VERSION ""

NS_ :

BS_:

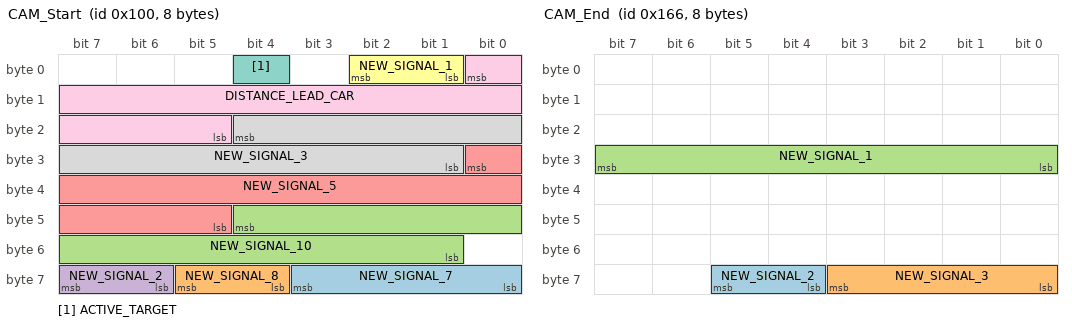
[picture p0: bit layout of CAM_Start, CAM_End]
BO_ 256 CAM_Start: 8 XXX
 SG_ NEW_SIGNAL_7 : 56|4@1+ (1,0) [0|15] "" XXX
 SG_ NEW_SIGNAL_8 : 61|2@0+ (1,0) [0|15] "" XXX
 SG_ NEW_SIGNAL_10 : 44|12@0+ (1,0) [0|15] "" XXX
 SG_ NEW_SIGNAL_2 : 63|2@0+ (1,0) [0|3] "" XXX
 SG_ NEW_SIGNAL_5 : 24|12@0+ (1,0) [0|255] "" XXX
 SG_ NEW_SIGNAL_1 : 2|2@0+ (1,0) [0|1] "" XXX
 SG_ ACTIVE_TARGET : 4|1@0+ (1,0) [0|1] "" XXX
 SG_ NEW_SIGNAL_3 : 20|12@0+ (1,0) [0|7] "" XXX
 SG_ DISTANCE_LEAD_CAR : 0|12@0+ (1,0) [0|255] "" XXX

BO_ 358 CAM_End: 8 XXX
 SG_ NEW_SIGNAL_2 : 61|2@0+ (1,0) [0|3] "" XXX
 SG_ NEW_SIGNAL_3 : 59|4@0+ (1,0) [0|15] "" XXX
 SG_ NEW_SIGNAL_1 : 31|8@0+ (1,0) [0|255] "" XXX

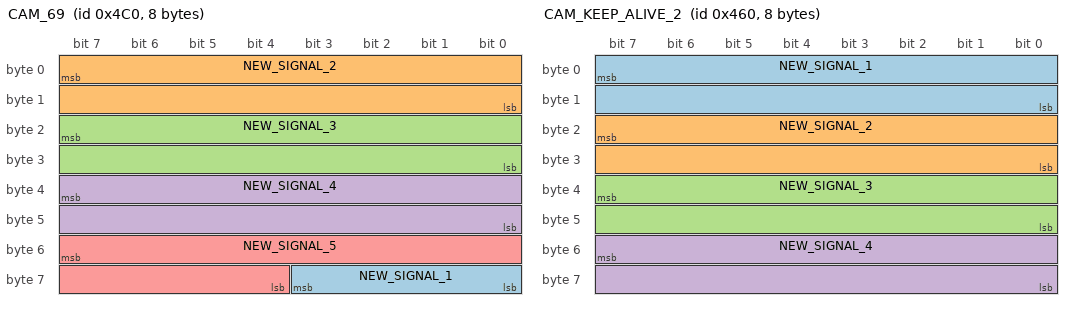
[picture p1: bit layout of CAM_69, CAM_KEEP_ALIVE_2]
BO_ 1216 CAM_69: 8 XXX
 SG_ NEW_SIGNAL_1 : 56|4@1+ (1,0) [0|15] "" XXX
 SG_ NEW_SIGNAL_2 : 7|16@0+ (1,0) [0|65535] "" XXX
 SG_ NEW_SIGNAL_3 : 23|16@0+ (1,0) [0|65535] "" XXX
 SG_ NEW_SIGNAL_4 : 39|16@0+ (1,0) [0|65535] "" XXX
 SG_ NEW_SIGNAL_5 : 55|12@0+ (1,0) [0|7] "" XXX

BO_ 1120 CAM_KEEP_ALIVE_2: 8 XXX
 SG_ NEW_SIGNAL_1 : 7|16@0+ (1,0) [0|65535] "" XXX
 SG_ NEW_SIGNAL_2 : 23|16@0+ (1,0) [0|65535] "" XXX
 SG_ NEW_SIGNAL_3 : 39|16@0+ (1,0) [0|65535] "" XXX
 SG_ NEW_SIGNAL_4 : 55|16@0+ (1,0) [0|65535] "" XXX

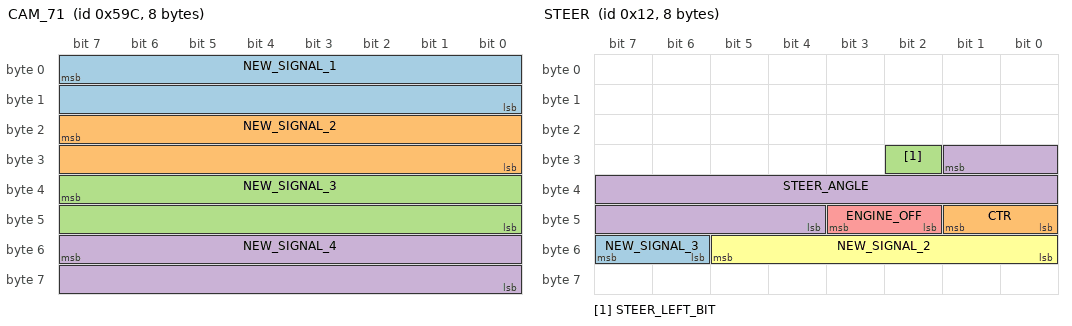
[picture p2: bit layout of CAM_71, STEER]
BO_ 1436 CAM_71: 8 XXX
 SG_ NEW_SIGNAL_1 : 7|16@0+ (1,0) [0|255] "" XXX
 SG_ NEW_SIGNAL_2 : 23|16@0+ (1,0) [0|65535] "" XXX
 SG_ NEW_SIGNAL_3 : 39|16@0+ (1,0) [0|65535] "" XXX
 SG_ NEW_SIGNAL_4 : 55|16@0+ (1,0) [0|65535] "" XXX

BO_ 18 STEER: 8 XXX
 SG_ NEW_SIGNAL_3 : 55|2@0+ (1,0) [0|15] "" XXX
 SG_ CTR : 41|2@0+ (1,0) [0|3] "" XXX
 SG_ STEER_LEFT_BIT : 26|1@0+ (1,0) [0|1] "" XXX
 SG_ STEER_ANGLE : 25|14@0- (1,375) [0|65536] "" XXX
 SG_ ENGINE_OFF : 43|2@0+ (1,0) [0|63] "" XXX
 SG_ NEW_SIGNAL_2 : 53|6@0+ (1,0) [0|15] "" XXX

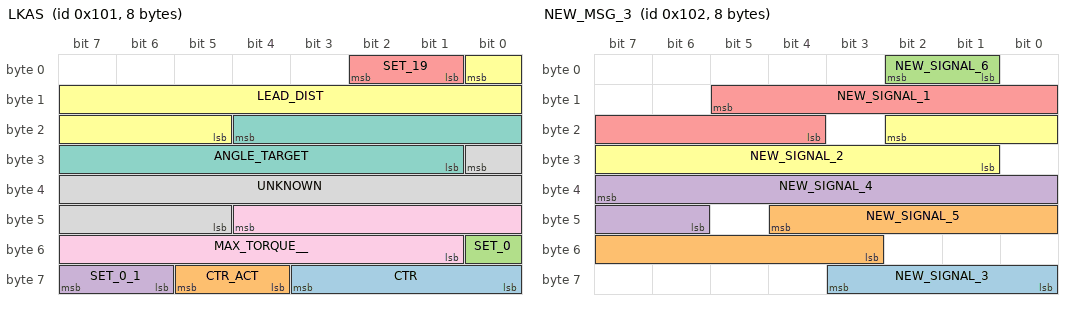
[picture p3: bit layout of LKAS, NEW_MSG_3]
BO_ 257 LKAS: 8 XXX
 SG_ CTR : 59|4@0+ (1,0) [0|255] "" XXX
 SG_ CTR_ACT : 61|2@0+ (1,0) [0|3] "" XXX
 SG_ SET_0 : 48|1@1+ (1,0) [0|3] "" XXX
 SG_ SET_0_1 : 63|2@0+ (1,0) [0|3] "" XXX
 SG_ SET_19 : 2|2@0+ (1,0) [0|255] "" XXX
 SG_ LEAD_DIST : 0|12@0+ (1,0) [0|255] "" XXX
 SG_ ANGLE_TARGET : 20|12@0+ (1,0) [0|4095] "" XXX
 SG_ UNKNOWN : 24|12@0+ (1,0) [0|4095] "" XXX
 SG_ MAX_TORQUE__ : 44|12@0- (1,0) [0|4095] "" XXX

BO_ 258 NEW_MSG_3: 8 XXX
 SG_ NEW_SIGNAL_3 : 59|4@0+ (1,0) [0|255] "" XXX
 SG_ NEW_SIGNAL_5 : 44|10@0- (1,0) [0|1] "" XXX
 SG_ NEW_SIGNAL_6 : 1|2@1+ (1,0) [0|3] "" XXX
 SG_ NEW_SIGNAL_4 : 39|10@0- (1,0) [0|1] "" XXX
 SG_ NEW_SIGNAL_1 : 13|10@0- (1,0) [0|255] "" XXX
 SG_ NEW_SIGNAL_2 : 18|10@0- (1,0) [0|255] "" XXX

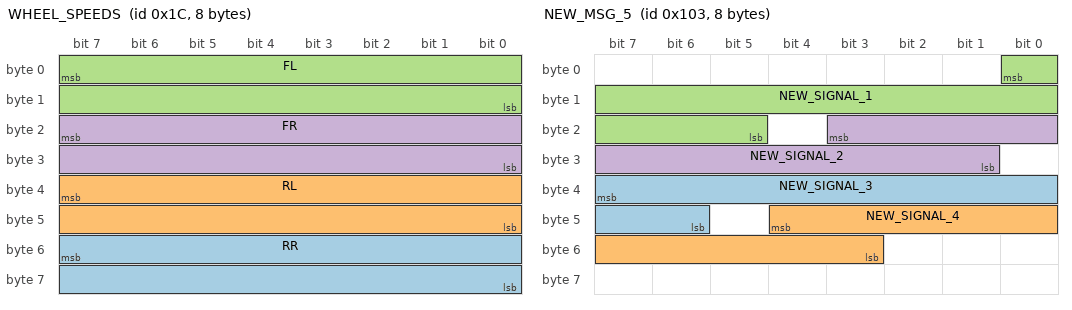
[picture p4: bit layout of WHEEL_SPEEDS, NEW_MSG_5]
BO_ 28 WHEEL_SPEEDS: 8 XXX
 SG_ RR : 55|16@0+ (0.01,-100) [0|65535] "" XXX
 SG_ RL : 39|16@0+ (0.01,-102) [0|65535] "" XXX
 SG_ FL : 7|16@0+ (0.01,-100) [0|65535] "" XXX
 SG_ FR : 23|16@0+ (0.01,-100) [0|65535] "" XXX

BO_ 259 NEW_MSG_5: 8 XXX
 SG_ NEW_SIGNAL_3 : 39|10@0- (1,0) [0|1] "" XXX
 SG_ NEW_SIGNAL_4 : 44|10@0- (1,0) [0|1] "" XXX
 SG_ NEW_SIGNAL_1 : 0|12@0- (1,0) [0|255] "" XXX
 SG_ NEW_SIGNAL_2 : 19|11@0- (1,0) [0|10000000] "" XXX

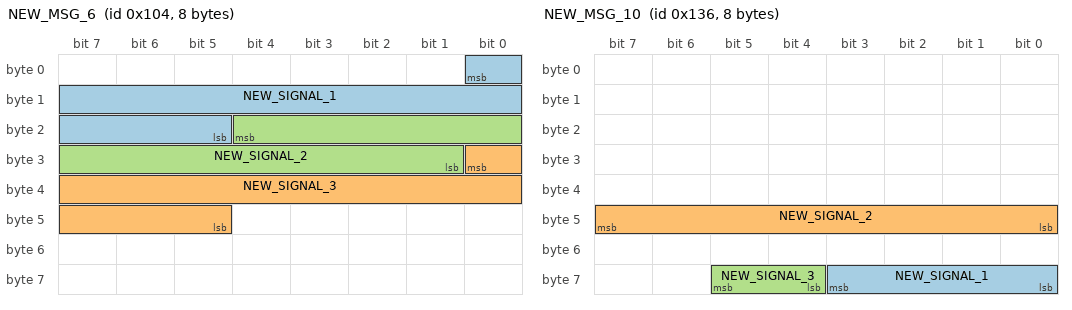
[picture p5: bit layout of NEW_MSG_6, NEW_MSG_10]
BO_ 260 NEW_MSG_6: 8 XXX
 SG_ NEW_SIGNAL_1 : 0|12@0+ (1,0) [0|255] "" XXX
 SG_ NEW_SIGNAL_3 : 24|12@0+ (1,0) [0|1] "" XXX
 SG_ NEW_SIGNAL_2 : 20|12@0- (1,0) [0|1] "" XXX

BO_ 261 NEW_MSG_7: 8 XXX
 SG_ NEW_SIGNAL_1 : 15|8@0+ (1,0) [0|255] "" XXX

BO_ 262 NEW_MSG_8: 8 XXX
 SG_ NEW_SIGNAL_1 : 15|8@0- (1,0) [0|255] "" XXX
 SG_ NEW_SIGNAL_2 : 7|8@0+ (1,0) [0|255] "" XXX

BO_ 263 NEW_MSG_9: 8 XXX
 SG_ NEW_SIGNAL_1 : 15|8@0+ (1,0) [0|255] "" XXX

BO_ 310 NEW_MSG_10: 8 XXX
 SG_ NEW_SIGNAL_1 : 56|4@1+ (1,0) [0|255] "" XXX
 SG_ NEW_SIGNAL_2 : 47|8@0+ (1,0) [0|255] "" XXX
 SG_ NEW_SIGNAL_3 : 61|2@0+ (1,0) [0|3] "" XXX

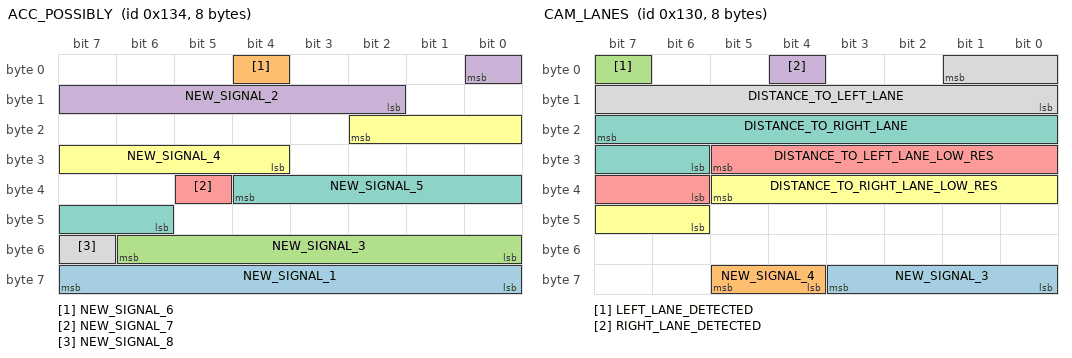
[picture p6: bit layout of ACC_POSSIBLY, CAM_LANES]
BO_ 308 ACC_POSSIBLY: 8 XXX
 SG_ NEW_SIGNAL_1 : 63|8@0+ (1,0) [0|255] "" XXX
 SG_ NEW_SIGNAL_6 : 4|1@0+ (1,0) [0|255] "" XXX
 SG_ NEW_SIGNAL_3 : 54|7@0+ (1,0) [0|15] "" XXX
 SG_ NEW_SIGNAL_2 : 0|7@0+ (1,0) [0|63] "" XXX
 SG_ NEW_SIGNAL_7 : 37|1@0+ (1,0) [0|1] "" XXX
 SG_ NEW_SIGNAL_4 : 18|7@0+ (1,0) [0|15] "" XXX
 SG_ NEW_SIGNAL_5 : 36|7@0+ (1,0) [0|1] "" XXX
 SG_ NEW_SIGNAL_8 : 55|1@0+ (1,0) [0|1] "" XXX

BO_ 304 CAM_LANES: 8 XXX
 SG_ NEW_SIGNAL_3 : 59|4@0+ (1,0) [0|255] "" XXX
 SG_ NEW_SIGNAL_4 : 61|2@0+ (1,0) [0|3] "" XXX
 SG_ LEFT_LANE_DETECTED : 7|1@0+ (1,0) [0|1] "" XXX
 SG_ RIGHT_LANE_DETECTED : 4|1@0+ (1,0) [0|255] "" XXX
 SG_ DISTANCE_TO_LEFT_LANE_LOW_RES : 29|8@0+ (1,0) [0|4095] "" XXX
 SG_ DISTANCE_TO_RIGHT_LANE_LOW_RES : 37|8@0+ (1,0) [0|15] "" XXX
 SG_ DISTANCE_TO_RIGHT_LANE : 23|10@0- (1,0) [0|2047] "" XXX
 SG_ DISTANCE_TO_LEFT_LANE : 1|10@0- (1,0) [0|1] "" XXX

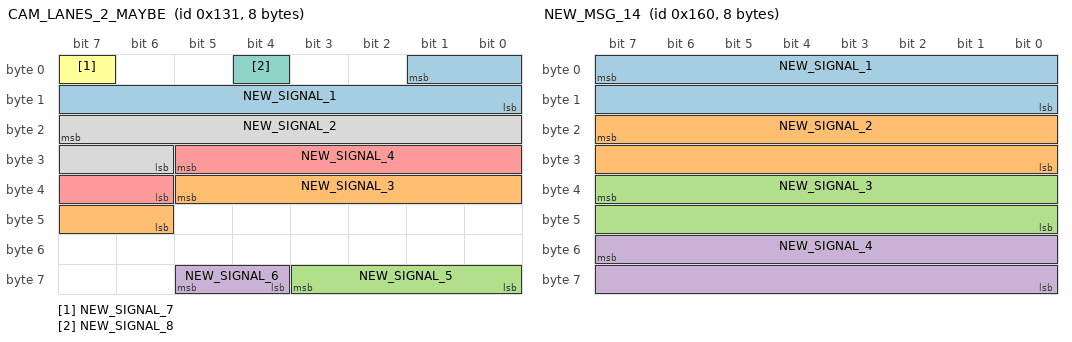
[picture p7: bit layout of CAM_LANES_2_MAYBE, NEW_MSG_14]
BO_ 305 CAM_LANES_2_MAYBE: 8 XXX
 SG_ NEW_SIGNAL_1 : 1|10@0+ (1,0) [0|255] "" XXX
 SG_ NEW_SIGNAL_3 : 37|8@0+ (1,0) [0|15] "" XXX
 SG_ NEW_SIGNAL_5 : 56|4@1+ (1,0) [0|15] "" XXX
 SG_ NEW_SIGNAL_6 : 61|2@0+ (1,0) [0|3] "" XXX
 SG_ NEW_SIGNAL_4 : 29|8@0+ (1,0) [0|1] "" XXX
 SG_ NEW_SIGNAL_7 : 7|1@0+ (1,0) [0|1] "" XXX
 SG_ NEW_SIGNAL_8 : 4|1@0+ (1,0) [0|1] "" XXX
 SG_ NEW_SIGNAL_2 : 23|10@0+ (1,0) [0|4095] "" XXX

BO_ 352 NEW_MSG_14: 8 XXX
 SG_ NEW_SIGNAL_1 : 7|16@0+ (1,0) [0|255] "" XXX
 SG_ NEW_SIGNAL_2 : 23|16@0+ (1,0) [0|65535] "" XXX
 SG_ NEW_SIGNAL_3 : 39|16@0+ (1,0) [0|65535] "" XXX
 SG_ NEW_SIGNAL_4 : 55|16@0+ (1,0) [0|65535] "" XXX

BO_ 355 NEW_MSG_15: 8 XXX
 SG_ NEW_SIGNAL_1 : 7|8@0+ (1,0) [0|127] "" XXX

BO_ 356 NEW_MSG_16: 8 XXX
 SG_ NEW_SIGNAL_1 : 56|4@1+ (1,0) [0|15] "" XXX
 SG_ NEW_SIGNAL_2 : 61|2@0+ (1,0) [0|3] "" XXX

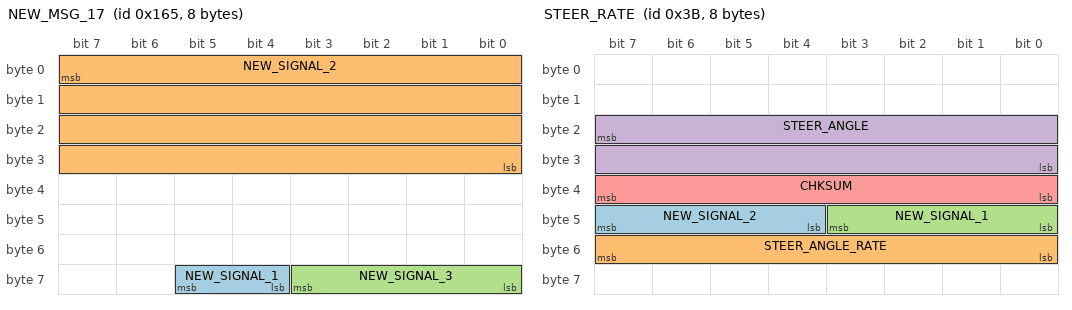
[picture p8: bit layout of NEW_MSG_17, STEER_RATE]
BO_ 357 NEW_MSG_17: 8 XXX
 SG_ NEW_SIGNAL_1 : 61|2@0+ (1,0) [0|3] "" XXX
 SG_ NEW_SIGNAL_2 : 7|32@0+ (1,0) [0|4294967295] "" XXX
 SG_ NEW_SIGNAL_3 : 56|4@1+ (1,0) [0|15] "" XXX

BO_ 59 STEER_RATE: 8 XXX
 SG_ NEW_SIGNAL_2 : 47|4@0+ (1,0) [0|15] "" XXX
 SG_ STEER_ANGLE_RATE : 55|8@0+ (0.05,0) [0|65535] "" XXX
 SG_ NEW_SIGNAL_1 : 43|4@0+ (1,0) [0|15] "" XXX
 SG_ STEER_ANGLE : 23|16@0+ (0.05,-1600) [-500|500] "" XXX
 SG_ CHKSUM : 39|8@0+ (1,0) [0|15] "" XXX

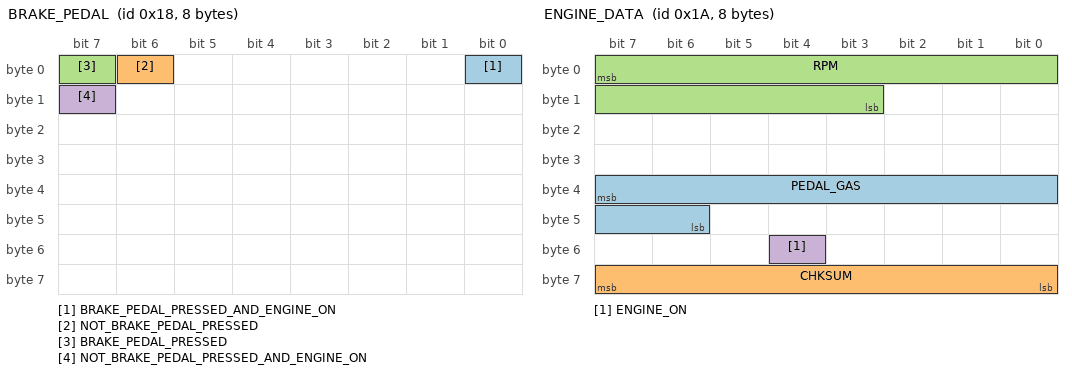
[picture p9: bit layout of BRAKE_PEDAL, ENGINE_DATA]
BO_ 24 BRAKE_PEDAL: 8 XXX
 SG_ BRAKE_PEDAL_PRESSED_AND_ENGINE_ON : 0|1@0+ (1,0) [0|3] "" XXX
 SG_ NOT_BRAKE_PEDAL_PRESSED : 6|1@0+ (1,0) [0|3] "" XXX
 SG_ BRAKE_PEDAL_PRESSED : 7|1@0+ (1,0) [0|65535] "" XXX
 SG_ NOT_BRAKE_PEDAL_PRESSED_AND_ENGINE_ON : 15|1@0+ (1,0) [0|7] "" XXX

BO_ 26 ENGINE_DATA: 8 XXX
 SG_ PEDAL_GAS : 39|10@0+ (1,0) [0|15] "" XXX
 SG_ CHKSUM : 63|8@0- (1,0) [0|15] "" XXX
 SG_ RPM : 7|13@0+ (1,0) [0|15] "" XXX
 SG_ ENGINE_ON : 52|1@0+ (1,0) [0|15] "" XXX

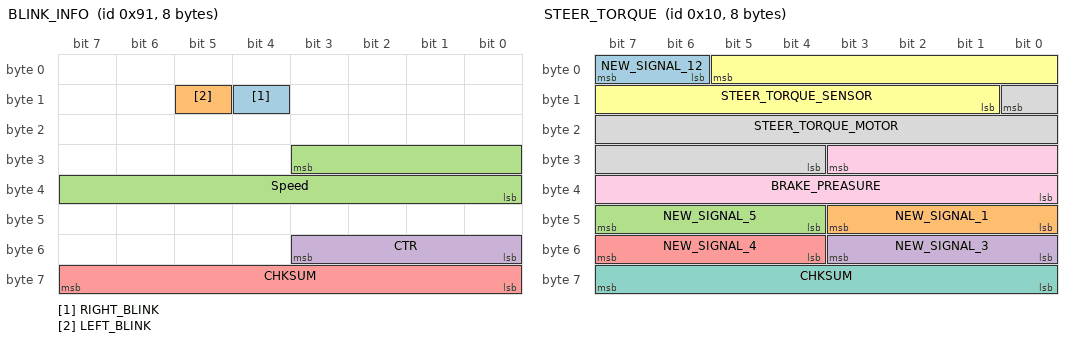
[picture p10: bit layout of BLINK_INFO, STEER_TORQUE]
BO_ 145 BLINK_INFO: 8 XXX
 SG_ RIGHT_BLINK : 12|1@0+ (1,0) [0|3] "" XXX
 SG_ LEFT_BLINK : 13|1@0+ (1,0) [0|3] "" XXX
 SG_ Speed : 27|12@0+ (1,0) [0|255] "" XXX
 SG_ CTR : 51|4@0+ (1,0) [0|15] "" XXX
 SG_ CHKSUM : 63|8@0+ (1,0) [0|15] "" XXX

BO_ 16 STEER_TORQUE: 8 XXX
 SG_ NEW_SIGNAL_12 : 7|2@0+ (1,0) [0|15] "" XXX
 SG_ NEW_SIGNAL_1 : 43|4@0+ (1,0) [0|15] "" XXX
 SG_ NEW_SIGNAL_5 : 47|4@0+ (1,0) [0|15] "" XXX
 SG_ NEW_SIGNAL_3 : 51|4@0+ (1,0) [0|15] "" XXX
 SG_ NEW_SIGNAL_4 : 55|4@0+ (1,0) [0|15] "" XXX
 SG_ STEER_TORQUE_SENSOR : 5|13@0+ (1,-4000) [0|15] "" XXX
 SG_ CHKSUM : 63|8@0- (1,0) [0|15] "" XXX
 SG_ STEER_TORQUE_MOTOR : 8|13@0+ (0.05,-205) [0|15] "" XXX
 SG_ BRAKE_PREASURE : 27|12@0+ (1,0) [0|15] "" XXX

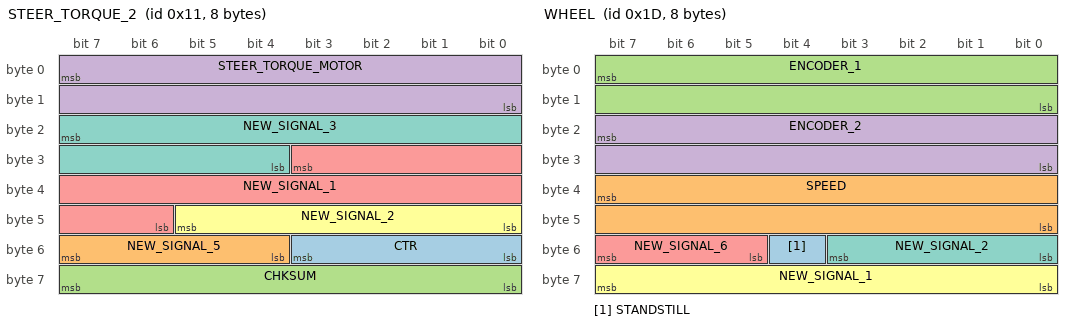
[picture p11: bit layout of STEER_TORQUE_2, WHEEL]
BO_ 17 STEER_TORQUE_2: 8 XXX
 SG_ CTR : 51|4@0+ (1,0) [0|15] "" XXX
 SG_ NEW_SIGNAL_5 : 55|4@0+ (1,0) [0|15] "" XXX
 SG_ CHKSUM : 63|8@0+ (1,0) [0|255] "" XXX
 SG_ STEER_TORQUE_MOTOR : 7|16@0+ (1,0) [0|255] "" XXX
 SG_ NEW_SIGNAL_1 : 27|14@0+ (1,0) [0|255] "" XXX
 SG_ NEW_SIGNAL_2 : 45|6@0+ (1,0) [0|15] "" XXX
 SG_ NEW_SIGNAL_3 : 23|12@0+ (1,0) [0|255] "" XXX

BO_ 29 WHEEL: 8 XXX
 SG_ STANDSTILL : 52|1@0+ (1,0) [0|15] "" XXX
 SG_ SPEED : 39|16@0+ (1,0) [0|127] "" XXX
 SG_ ENCODER_1 : 7|16@0+ (1,0) [0|65535] "" XXX
 SG_ ENCODER_2 : 23|16@0+ (1,0) [0|65535] "" XXX
 SG_ NEW_SIGNAL_6 : 55|3@0+ (1,0) [0|7] "" XXX
 SG_ NEW_SIGNAL_1 : 63|8@0+ (1,0) [0|255] "" XXX
 SG_ NEW_SIGNAL_2 : 51|4@0+ (1,0) [0|15] "" XXX

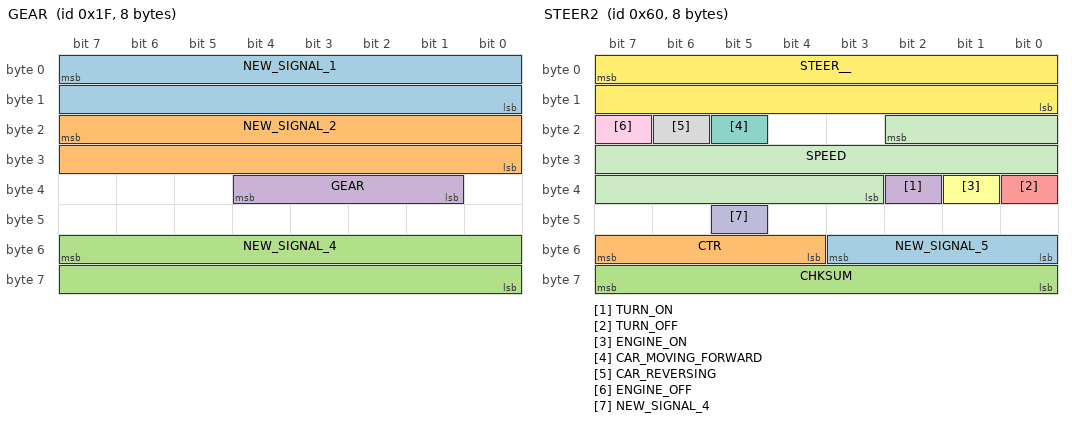
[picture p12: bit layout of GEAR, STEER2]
BO_ 31 GEAR: 8 XXX
 SG_ NEW_SIGNAL_1 : 7|16@0+ (1,0) [0|65535] "" XXX
 SG_ NEW_SIGNAL_2 : 23|16@0+ (1,0) [0|65535] "" XXX
 SG_ NEW_SIGNAL_4 : 55|16@0+ (1,0) [0|65535] "" XXX
 SG_ GEAR : 36|4@0+ (1,0) [0|65535] "" XXX

BO_ 96 STEER2: 8 XXX
 SG_ NEW_SIGNAL_5 : 48|4@1+ (1,0) [0|15] "" XXX
 SG_ CTR : 55|4@0+ (1,0) [0|15] "" XXX
 SG_ CHKSUM : 63|8@0+ (1,0) [0|255] "" XXX
 SG_ TURN_ON : 34|1@0+ (1,0) [0|1] "" XXX
 SG_ TURN_OFF : 32|1@0+ (1,0) [0|1] "" XXX
 SG_ ENGINE_ON : 33|1@0+ (1,0) [0|1] "" XXX
 SG_ CAR_MOVING_FORWARD : 21|1@0+ (1,0) [0|15] "" XXX
 SG_ CAR_REVERSING : 22|1@0+ (1,0) [0|1] "" XXX
 SG_ ENGINE_OFF : 23|1@0+ (1,0) [0|1] "" XXX
 SG_ NEW_SIGNAL_4 : 45|1@0+ (1,0) [0|15] "" XXX
 SG_ SPEED : 18|16@0- (0.00621371,-62.1371) [-65635|65635] "MPH" XXX
 SG_ STEER__ : 7|16@0+ (1,0) [0|65535] "" XXX

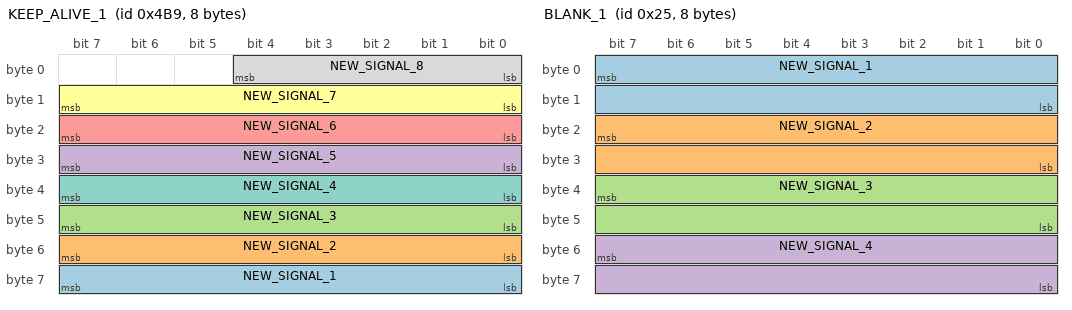
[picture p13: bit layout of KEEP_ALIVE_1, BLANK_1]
BO_ 1209 KEEP_ALIVE_1: 8 XXX
 SG_ NEW_SIGNAL_1 : 63|8@0+ (1,0) [0|255] "" XXX
 SG_ NEW_SIGNAL_2 : 55|8@0+ (1,0) [0|255] "" XXX
 SG_ NEW_SIGNAL_3 : 47|8@0+ (1,0) [0|255] "" XXX
 SG_ NEW_SIGNAL_5 : 31|8@0+ (1,0) [0|255] "" XXX
 SG_ NEW_SIGNAL_6 : 23|8@0+ (1,0) [0|255] "" XXX
 SG_ NEW_SIGNAL_7 : 15|8@0+ (1,0) [0|255] "" XXX
 SG_ NEW_SIGNAL_4 : 39|8@0+ (1,0) [0|255] "" XXX
 SG_ NEW_SIGNAL_8 : 4|5@0+ (1,0) [0|127] "" XXX

BO_ 37 BLANK_1: 8 XXX
 SG_ NEW_SIGNAL_1 : 7|16@0+ (1,0) [0|65535] "" XXX
 SG_ NEW_SIGNAL_2 : 23|16@0+ (1,0) [0|65535] "" XXX
 SG_ NEW_SIGNAL_3 : 39|16@0+ (1,0) [0|65535] "" XXX
 SG_ NEW_SIGNAL_4 : 55|16@0+ (1,0) [0|65535] "" XXX

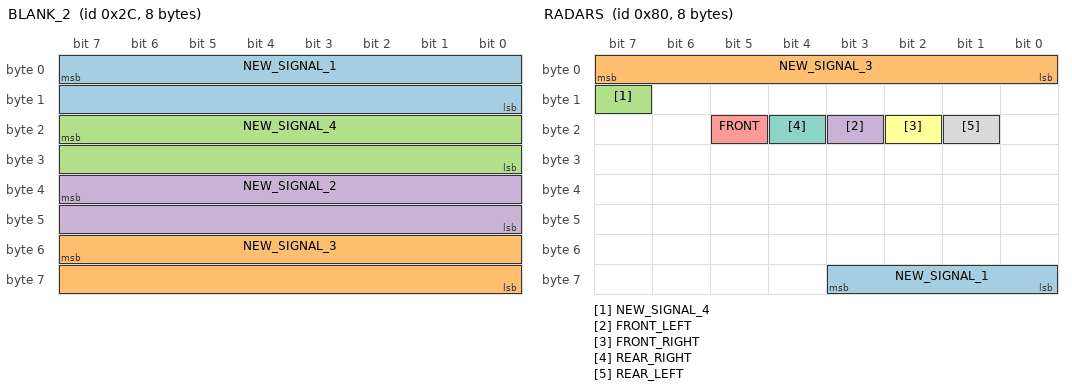
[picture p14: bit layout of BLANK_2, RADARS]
BO_ 44 BLANK_2: 8 XXX
 SG_ NEW_SIGNAL_1 : 7|16@0+ (1,0) [0|16777215] "" XXX
 SG_ NEW_SIGNAL_3 : 55|16@0+ (1,0) [0|65535] "" XXX
 SG_ NEW_SIGNAL_4 : 23|16@0+ (1,0) [0|65535] "" XXX
 SG_ NEW_SIGNAL_2 : 39|16@0+ (1,0) [0|16777215] "" XXX

BO_ 128 RADARS: 8 XXX
 SG_ NEW_SIGNAL_1 : 59|4@0+ (1,0) [0|255] "" XXX
 SG_ NEW_SIGNAL_3 : 7|8@0+ (1,0) [0|255] "" XXX
 SG_ NEW_SIGNAL_4 : 15|1@0+ (1,0) [0|255] "" XXX
 SG_ FRONT_LEFT : 19|1@0+ (1,0) [0|255] "" XXX
 SG_ FRONT : 21|1@0+ (1,0) [0|1] "" XXX
 SG_ FRONT_RIGHT : 18|1@0+ (1,0) [0|1] "" XXX
 SG_ REAR_RIGHT : 20|1@0+ (1,0) [0|15] "" XXX
 SG_ REAR_LEFT : 17|1@0+ (1,0) [0|1] "" XXX

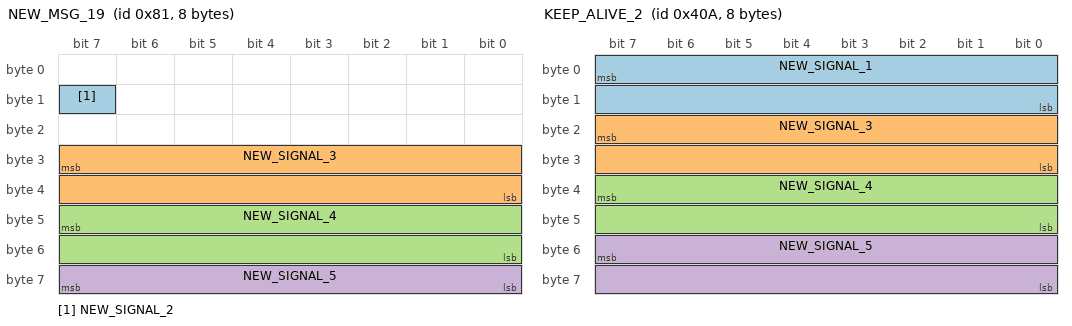
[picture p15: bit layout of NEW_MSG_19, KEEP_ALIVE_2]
BO_ 129 NEW_MSG_19: 8 XXX
 SG_ NEW_SIGNAL_2 : 15|1@0+ (1,0) [0|65535] "" XXX
 SG_ NEW_SIGNAL_3 : 31|16@0+ (1,0) [0|65535] "" XXX
 SG_ NEW_SIGNAL_4 : 47|16@0+ (1,0) [0|65535] "" XXX
 SG_ NEW_SIGNAL_5 : 56|8@1+ (1,0) [0|15] "" XXX

BO_ 1034 KEEP_ALIVE_2: 8 XXX
 SG_ NEW_SIGNAL_1 : 7|16@0+ (1,0) [0|255] "" XXX
 SG_ NEW_SIGNAL_3 : 23|16@0+ (1,0) [0|255] "" XXX
 SG_ NEW_SIGNAL_4 : 39|16@0+ (1,0) [0|255] "" XXX
 SG_ NEW_SIGNAL_5 : 55|16@0+ (1,0) [0|255] "" XXX

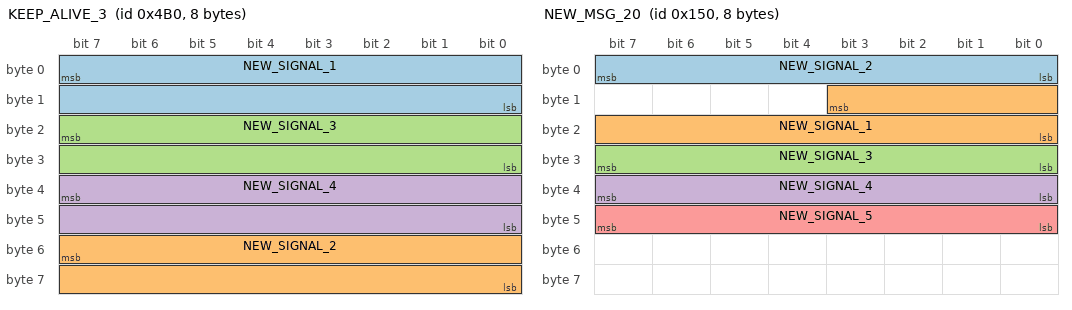
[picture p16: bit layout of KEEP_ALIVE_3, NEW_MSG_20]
BO_ 1200 KEEP_ALIVE_3: 8 XXX
 SG_ NEW_SIGNAL_1 : 7|16@0+ (1,0) [0|255] "" XXX
 SG_ NEW_SIGNAL_2 : 55|16@0+ (1,0) [0|255] "" XXX
 SG_ NEW_SIGNAL_3 : 23|16@0+ (1,0) [0|65535] "" XXX
 SG_ NEW_SIGNAL_4 : 39|16@0+ (1,0) [0|65535] "" XXX

BO_ 354 CAM_KEEP_ALIVE_1: 8 XXX
 SG_ NEW_SIGNAL_1 : 7|16@0+ (1,0) [0|65535] "" XXX
 SG_ NEW_SIGNAL_2 : 23|16@0+ (1,0) [0|65535] "" XXX
 SG_ NEW_SIGNAL_3 : 39|16@0+ (1,0) [0|65535] "" XXX
 SG_ NEW_SIGNAL_4 : 55|30@0+ (1,0) [0|65535] "" XXX

BO_ 336 NEW_MSG_20: 8 XXX
 SG_ NEW_SIGNAL_2 : 7|8@0+ (1,0) [0|4095] "" XXX
 SG_ NEW_SIGNAL_1 : 11|12@0+ (1,0) [0|127] "" XXX
 SG_ NEW_SIGNAL_3 : 31|8@0+ (1,0) [0|255] "" XXX
 SG_ NEW_SIGNAL_4 : 39|8@0+ (1,0) [0|255] "" XXX
 SG_ NEW_SIGNAL_5 : 47|8@0+ (1,0) [0|255] "" XXX

BO_ 342 NEW_MSG_21: 8 XXX
 SG_ NEW_SIGNAL_1 : 56|4@1+ (1,0) [0|15] "" XXX
 SG_ NEW_SIGNAL_2 : 63|4@0+ (1,0) [0|15] "" XXX
 SG_ NEW_SIGNAL_4 : 55|4@0+ (1,0) [0|15] "" XXX
 SG_ NEW_SIGNAL_5 : 39|16@0+ (1,0) [0|15] "" XXX
 SG_ NEW_SIGNAL_3 : 48|4@1+ (1,0) [0|15] "" XXX
 SG_ NEW_SIGNAL_7 : 7|16@0+ (1,0) [0|255] "" XXX
 SG_ NEW_SIGNAL_8 : 23|16@0+ (1,0) [0|65535] "" XXX
 SG_ NEW_SIGNAL_6 : 40|4@1+ (1,0) [0|15] "" XXX

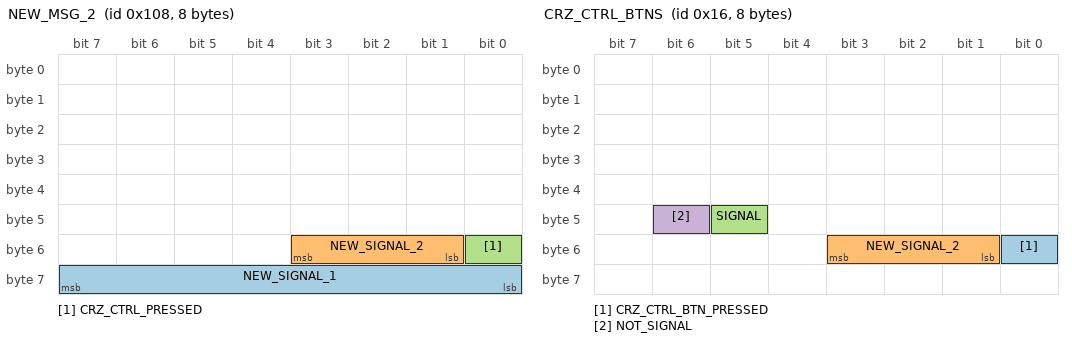
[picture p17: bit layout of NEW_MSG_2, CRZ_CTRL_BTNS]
BO_ 264 NEW_MSG_2: 8 XXX
 SG_ NEW_SIGNAL_1 : 56|8@1+ (1,0) [0|15] "" XXX
 SG_ NEW_SIGNAL_2 : 49|3@1+ (1,0) [0|7] "" XXX
 SG_ CRZ_CTRL_PRESSED : 48|1@0+ (1,0) [0|1] "" XXX

BO_ 22 CRZ_CTRL_BTNS: 8 XXX
 SG_ CRZ_CTRL_BTN_PRESSED : 48|1@0+ (1,0) [0|1] "" XXX
 SG_ NEW_SIGNAL_2 : 51|3@0+ (1,0) [0|7] "" XXX
 SG_ SIGNAL : 45|1@0+ (1,0) [0|15] "" XXX
 SG_ NOT_SIGNAL : 46|1@0+ (1,0) [0|3] "" XXX

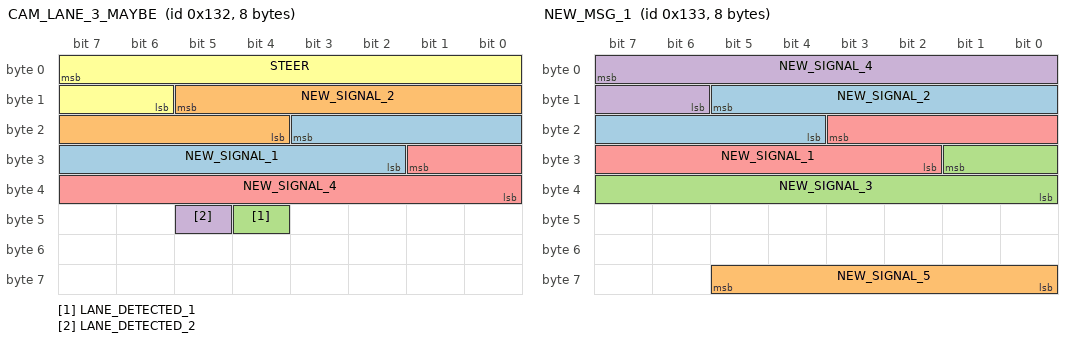
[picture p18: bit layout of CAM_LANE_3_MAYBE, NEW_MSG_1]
BO_ 306 CAM_LANE_3_MAYBE: 8 XXX
 SG_ NEW_SIGNAL_1 : 19|10@0+ (1,0) [0|63] "" XXX
 SG_ NEW_SIGNAL_2 : 13|10@0+ (1,0) [0|255] "" XXX
 SG_ LANE_DETECTED_1 : 44|1@0+ (1,0) [0|1] "" XXX
 SG_ LANE_DETECTED_2 : 45|1@0+ (1,0) [0|1] "" XXX
 SG_ NEW_SIGNAL_4 : 25|10@0+ (1,0) [0|1] "" XXX
 SG_ STEER : 7|10@0+ (1,0) [0|1] "" XXX

BO_ 307 NEW_MSG_1: 8 XXX
 SG_ NEW_SIGNAL_2 : 13|10@0+ (1,0) [0|1] "" XXX
 SG_ NEW_SIGNAL_5 : 61|6@0+ (1,0) [0|1] "" XXX
 SG_ NEW_SIGNAL_3 : 25|10@0+ (1,0) [0|1] "" XXX
 SG_ NEW_SIGNAL_4 : 7|10@0+ (1,0) [0|1] "" XXX
 SG_ NEW_SIGNAL_1 : 19|10@0+ (1,0) [0|1] "" XXX

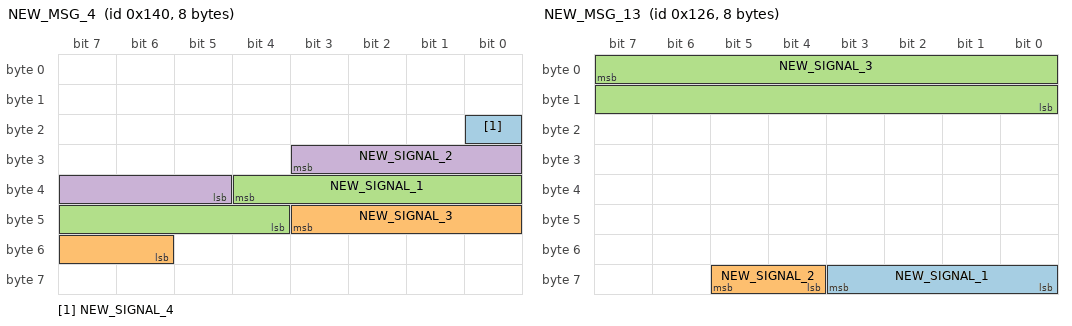
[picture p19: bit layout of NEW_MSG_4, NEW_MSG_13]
BO_ 320 NEW_MSG_4: 8 XXX
 SG_ NEW_SIGNAL_4 : 16|1@0+ (1,0) [0|255] "" XXX
 SG_ NEW_SIGNAL_3 : 43|6@0+ (1,0) [0|1] "" XXX
 SG_ NEW_SIGNAL_1 : 36|9@0+ (1,0) [0|1] "" XXX
 SG_ NEW_SIGNAL_2 : 27|7@0+ (1,0) [0|1] "" XXX

BO_ 321 NEW_MSG_11: 8 XXX
 SG_ NEW_SIGNAL_1 : 5|1@0+ (1,0) [0|1] "" XXX
 SG_ NEW_SIGNAL_2 : 32|1@0+ (1,0) [0|1] "" XXX

BO_ 293 NEW_MSG_12: 8 XXX
 SG_ NEW_SIGNAL_1 : 7|8@0+ (1,0) [0|255] "" XXX
 SG_ NEW_SIGNAL_2 : 39|16@0+ (1,0) [0|255] "" XXX
 SG_ NEW_SIGNAL_3 : 19|4@0+ (1,0) [0|1] "" XXX

BO_ 294 NEW_MSG_13: 8 XXX
 SG_ NEW_SIGNAL_1 : 59|4@0+ (1,0) [0|255] "" XXX
 SG_ NEW_SIGNAL_2 : 61|2@0+ (1,0) [0|1] "" XXX
 SG_ NEW_SIGNAL_3 : 7|16@0+ (1,0) [0|1] "" XXX

BO_ 292 NEW_MSG_18: 8 XXX
 SG_ NEW_SIGNAL_1 : 63|8@0+ (1,0) [0|255] "" XXX

BO_ 291 NEW_MSG_22: 8 XXX
 SG_ NEW_SIGNAL_1 : 39|8@0+ (1,0) [0|255] "" XXX

BO_ 290 NEW_MSG_23: 8 XXX
 SG_ NEW_SIGNAL_1 : 31|5@0+ (1,0) [0|255] "" XXX

BO_ 277 NEW_MSG_24: 8 XXX
 SG_ NEW_SIGNAL_1 : 47|8@0+ (1,0) [0|1] "" XXX

BO_ 278 NEW_MSG_25: 8 XXX

BO_ 273 NEW_MSG_26: 8 XXX
 SG_ NEW_SIGNAL_1 : 23|4@0+ (1,0) [0|3] "" XXX

BO_ 274 NEW_MSG_27: 8 XXX
 SG_ NEW_SIGNAL_1 : 39|8@0+ (1,0) [0|1] "" XXX

BO_ 289 NEW_MSG_28: 8 XXX
 SG_ NEW_SIGNAL_1 : 55|8@0+ (1,0) [0|1] "" XXX

BO_ 20 NEW_MSG_29: 8 XXX
 SG_ RIGHT_BLINK_CLOCK : 23|8@0+ (1,0) [0|1] "" XXX

BO_ 288 NEW_MSG_30: 8 XXX

BU_: PowertrainControlModule InstrumentCluster ElectricPowerSteering AntilockBrakeSystem

CM_ SG_ 134 LWI_Lenkradwinkel "Steering angle WITH variable ratio effect included";
CM_ SG_ 159 EPS_HCA_Status "Status of Heading Control Assist feature";
CM_ SG_ 159 EPS_Lenkmoment "Steering input by driver, torque";
CM_ SG_ 159 EPS_VZ_Lenkmoment "Steering input by driver, direction";
CM_ SG_ 159 EPS_Berechneter_LW "Raw steering angle, degrees";
CM_ SG_ 159 EPS_VZ_BLW "Raw steering angle, direction";
CM_ SG_ 173 COUNTERXX "Message not renamed to COUNTER because J533 rate-limiting makes it look like messages are being lost";
CM_ SG_ 294 HCA_01_Vib_Freq "Frequenz der Lenkradvibration";
CM_ SG_ 294 HCA_01_LM_Offset "Von HCA angefordertes Lenkmoment (Betrag)";
CM_ SG_ 294 EA_ACC_Sollstatus "Status-Anforderung ACC von Emergency Alert. Statuswechsel bei Flanke. Solange Wert=1, wird EA_ACC_Wunschgeschwindigkeit übernommen. Wert=2 führt zu Zustand ¿ACC_GRA_passiv¿";
CM_ SG_ 294 EA_Ruckprofil "Emergency Alert Anforderung an ESP, welcher Ruck verwendet werden soll. Eine Umsetzung der Ruckanforderung im ESP erfolgt nur mit gesetztem Bit 'EA_Ruckfreigabe'.";
CM_ SG_ 294 HCA_01_Sendestatus "Gibt den Sendestatus der HCA_01 an (notwendig für IL-Unterstützung)";
CM_ SG_ 294 HCA_01_LM_OffSign "Vorzeichen des HCA-Lenkmoments";
CM_ SG_ 294 HCA_01_Status_HCA "Statusinformation vom HCA und Manoevrierassistent für Handshakemechanismus mit der Lenkung";
CM_ SG_ 294 HCA_01_Vib_Amp "Momentenamplitude der Lenkradvibration";
CM_ SG_ 294 EA_Ruckfreigabe "Emergency Alert Freigabit für die Warnruck-Anforderung an das ESP";
CM_ SG_ 294 EA_ACC_Wunschgeschwindigkeit "Emergency Alert Anforderung neue Wunschgeschwindigkeit";
CM_ SG_ 302 ACC_Hold_Request "Active request for ABS brake hold in ACC_Hold_Type";
CM_ SG_ 302 ACC_Boost_Request "Hybrid engine start related";
CM_ SG_ 302 ACC_Freewheel_Request "Active request for DSG sailing/coasting in ACC_Freewheel_Type";
CM_ SG_ 302 ACC_Hold_Release "Request to ABS to release brake hold";
CM_ SG_ 302 ACC_Accel_Secondary "Target acceleration of the secondary controller";
CM_ SG_ 302 ACC_Accel_TSK "Mirror of request to TSK to implement a target acceleration";
CM_ SG_ 870 Hazard_Switch "Four-way flashers active";
CM_ SG_ 870 Comfort_Signal_Left "Comfort turn signal active, left";
CM_ SG_ 870 Comfort_Signal_Right "Comfort turn signal active, right";
CM_ SG_ 870 Left_Turn_Exterior_Bulb_1 "Probably front";
CM_ SG_ 870 Right_Turn_Exterior_Bulb_1 "Probably front";
CM_ SG_ 870 Left_Turn_Exterior_Bulb_2 "Probably rear";
CM_ SG_ 870 Right_Turn_Exterior_Bulb_2 "Probably rear";
CM_ SG_ 870 Fast_Send_Rate_Active "CAN message send rate";
CM_ SG_ 919 LDW_DLC "Probable DLC (distance to line crossing)";
CM_ SG_ 919 LDW_TLC "Probable TLC (time to line crossing)";
CM_ SG_ 919 LDW_Unknown "Might be a steering pressed / driver active flag";
CM_ SG_ 919 Alert_Message "Static table of alert messages to be invoked in the instrument cluster, some with or without beeps, 0 = no current message";
CM_ SG_ 919 LDW_Direction "Left/right indicator for DLC and TLC";
CM_ SG_ 919 Right_Lane_Status "Display brightness range, 0 = no lane, 3 = full brightness";
CM_ SG_ 919 Left_Lane_Status "Display brightness range, 0 = no lane, 3 = full brightness";
CM_ SG_ 919 Kombi_Lamp_Orange "Enables orange LDW light in instrument cluster";
CM_ SG_ 919 Kombi_Lamp_Green "Enables green LDW light in instrument cluster";
CM_ SG_ 780 Folgefahrt "Following another vehicle";
CM_ SG_ 780 SetAbstand "Set following distance";
CM_ SG_ 780 Abstand "Following distance";
CM_ SG_ 780 SetSpeed "ACC set speed";
CM_ SG_ 391 GearPosition "Traditional PRND plus B-mode aggressive regen, B-mode mapped to Drive";
CM_ SG_ 960 ZAS_Kl_15 "Indicates ignition on";
CM_ SG_ 1720 KBI_BCmE_aktiv "Anzeige BCmE aktiv (BCmE-Screen oder Einsparhinweis in der Anzeige)";
CM_ SG_ 1720 KBI_Max_Tankinhalt "Mitteilung des maximalen Tankinhalts an das Reichweitenmodul";
CM_ SG_ 1720 KBI_Nachtanken_erkannt "Statusinformation Nachtankmodus";
CM_ SG_ 1720 KBI_Reifenumfang "Mittlerer Radumfang aus der K-Zahl gerechnet in Millimeter.  Byte 2 Bit 5,4 reserviert, Byte 2 Bit 3..0 und Byte 1 Bit 7..0; Wertebereich 0..4096 mm
";
CM_ SG_ 1720 KBI_Reifenumfang_Sekundaer "Fahrzeuge mit unterschiedlichen Reifenumfängen Vorderachse / Hinterachse:

Primärachse: KBI_Reifenumfang
Sekundärachse: KBI_Reifenumfang_Sekundaer
";
CM_ SG_ 1720 KBI_Sparhinweis_quittiert "angezeigter Sparhinweis ist quittiert. Signal wird nach zwei Sendebotschaften wieder auf '0' gesetzt.";
CM_ SG_ 1720 KBI_Tankfuellstand_Prozent "Tankfüllstand in %";
CM_ SG_ 1720 KBI_Tankinhalt_hochaufl "angezeigter Tankinhalt hochauflösend zur Restreichweitenberechnung";
CM_ SG_ 1720 KBI_Variante "Zeigt an ob es sich um ein konventionelles Zeiger-Kombiinstrument handelt oder um eine Volldisplay-Kombiinstrument";
CM_ SG_ 1720 KBI_Variante_USA "In diesem Signal wird die HW-Variante des Kombis ausgegeben, ACC plausibilisiert auf dieses Signal hin seine US-Codierung";

VAL_ 357 Cruise_State 4 "active" 3 "standby" 0 "off" ;
VAL_ 970 Lkas_Action 15 "off" 9 "abrupt" 8 "abrupt2" 5 "smooth" 4 "smooth2" ;
VAL_ 970 Lkas_Alert 15 "no_alert" 3 "high_intensity" 2 "mid_intensity" 1 "low_intensity" ;
VAL_ 972 LaActAvail_D_Actl 3 "available" 2 "tbd" 1 "not_available" 0 "fault" ;
